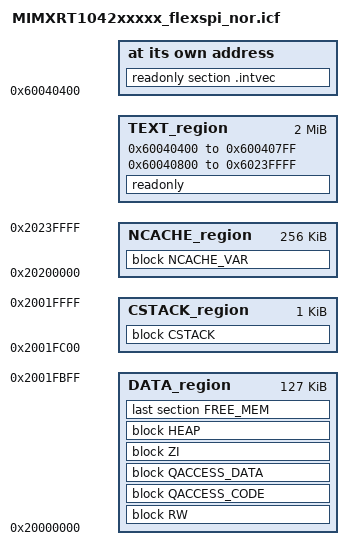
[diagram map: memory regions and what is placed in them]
/*
** ###################################################################
**     Processors:          MIMXRT1042DFP6B
**                          MIMXRT1042XFP5B
**                          MIMXRT1042XJM5B
**
**     Compiler:            IAR ANSI C/C++ Compiler for ARM
**     Reference manual:    IMXRT1040RM Rev.A, 09/2021
**     Version:             rev. 0.1, 2021-07-20
**     Build:               b211221
**
**     Abstract:
**         Linker file for the IAR ANSI C/C++ Compiler for ARM
**
**     Copyright 2016 Freescale Semiconductor, Inc.
**     Copyright 2016-2021 NXP
**     All rights reserved.
**
**     SPDX-License-Identifier: BSD-3-Clause
**
**     http:                 www.nxp.com
**     mail:                 support@nxp.com
**
** ###################################################################
*/

/* Primary application image is up to 2 MB in size including headers and interrupt vectors */

define symbol m_interrupts_start       = 0x60040400;
define symbol m_interrupts_end         = 0x600407FF;

define symbol m_text_start             = 0x60040800;
define symbol m_text_end               = 0x6023FFFF;

define symbol m_data_start             = 0x20000000;
define symbol m_data_end               = 0x2001FFFF;

define symbol m_ncache_start           = 0x20200000;
define symbol m_ncache_end             = 0x2023FFFF;

/* Sizes */
if (isdefinedsymbol(__stack_size__)) {
  define symbol __size_cstack__        = __stack_size__;
} else {
  define symbol __size_cstack__        = 0x0400;
}

if (isdefinedsymbol(__heap_size__)) {
  define symbol __size_heap__          = __heap_size__;
} else {
  define symbol __size_heap__          = 0x0400;
}

define exported symbol __NCACHE_REGION_START   = m_ncache_start;
define exported symbol __NCACHE_REGION_SIZE    = m_ncache_end - m_ncache_start + 1;

define exported symbol __VECTOR_TABLE          = m_interrupts_start;

define memory mem with size = 4G;
define region TEXT_region = mem:[from m_interrupts_start to m_interrupts_end]
                          | mem:[from m_text_start to m_text_end];
define region DATA_region = mem:[from m_data_start to m_data_end-__size_cstack__];
define region NCACHE_region = mem:[from m_ncache_start to m_ncache_end];
define region CSTACK_region = mem:[from m_data_end-__size_cstack__+1 to m_data_end];

define block CSTACK    with alignment = 8, size = __size_cstack__   { };
define block HEAP      with alignment = 8, size = __size_heap__     { };
define block RW        { readwrite };
define block ZI        { zi };
define block NCACHE_VAR    { section NonCacheable , section NonCacheable.init };
define block QACCESS_CODE  { section CodeQuickAccess };
define block QACCESS_DATA  { section DataQuickAccess };

initialize by copy {
  readwrite,

  /* Explicitly place flash operation functions in RAM. */
  object mflash_drv.o,
  object fsl_flexspi.o,
  object fsl_cache.o,

  section .textrw,
  section CodeQuickAccess,
  section DataQuickAccess
};

do not initialize  { section .noinit };

place at address mem: m_interrupts_start    { readonly section .intvec };

place in TEXT_region                        { readonly };
place in DATA_region                        { block RW };
place in DATA_region                        { block QACCESS_CODE };
place in DATA_region                        { block QACCESS_DATA };
place in DATA_region                        { block ZI };
place in DATA_region                        { block HEAP };
place in DATA_region                        { last section FREE_MEM};
place in CSTACK_region                      { block CSTACK };
place in NCACHE_region                      { block NCACHE_VAR };

keep { block HEAP, block CSTACK };
